# MPU register map
Vendor: Texas Instruments
Peripheral module from a debugger description file (folder awr2544).
Registers are 32-bit, read-only, no defined reset value unless marked. A register's access mark holds for its fields unless they carry their own. Offsets are as the file gives them; lines under a group give offsets from that group; [hi:lo] are bit positions; {n}, {i} and the like mark numbered series; 'fields as' and 'values as' point back to an identical list; <NAME> marks a mode.

## MPU
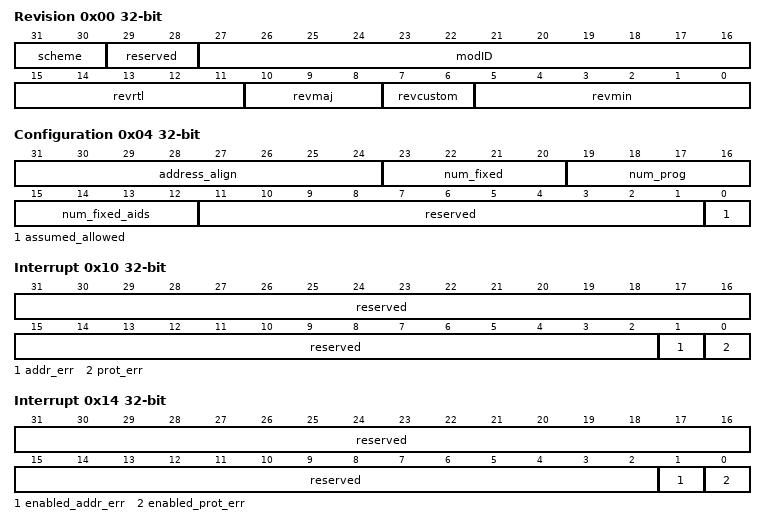
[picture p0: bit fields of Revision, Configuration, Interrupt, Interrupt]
0x00 Revision
  [31:30] scheme
  [29:28] reserved — Always read a s0. Writes have no affect.
  [27:16] modID — Module ID field.
  [15:11] revrtl — RTL revision.Will vary depending on release.
  [10:8] revmaj — Majo revision.
  [7:6] revcustom — Custom revision.
  [5:0] revmin — Minor revision.
0x04 Configuration
  [31:24] address_align — Address alignment for range checking.
  [23:20] num_fixed — Number of fixed address ranges Configurable as 0 or 1.
  [19:16] num_prog — Number of programmable address ranges.Value is determined by configuration
  [15:12] num_fixed_aids — Number of supported AIDs. 0 = no specific AIDs supported (all treated equally) N = PrivIDs from 0 to N-1 supported, others use AIDX
  [11:1] reserved — Always read as 0.
  [0] assumed_allowed — Assumed allowed mode. 0 = assumed disallowed, 1 = assumed allowed
0x10 Interrupt Raw Status/Set access not given
  [31:2] reserved ro — Always read as 0.
  [1] addr_err — Addressing violation error. Raw status is read.Write a 1 to set the status. Writing a 0 has no effect.
  [0] prot_err — Protection violation error. Raw status is read. Write a 1 to set the status. Writing a 0 has no effect.
0x14 Interrupt Enabled Status/Clear access not given
  [31:2] reserved ro — Always read as 0.
  [1] enabled_addr_err — Addressing violation error. Enabled status is read.Write a 1 to clear the status. Writing a 0 has no effect.
  [0] enabled_prot_err — Protection violation error. Enabled status is read. Write a 1 to clear the status. Writing a 0 has no effect.
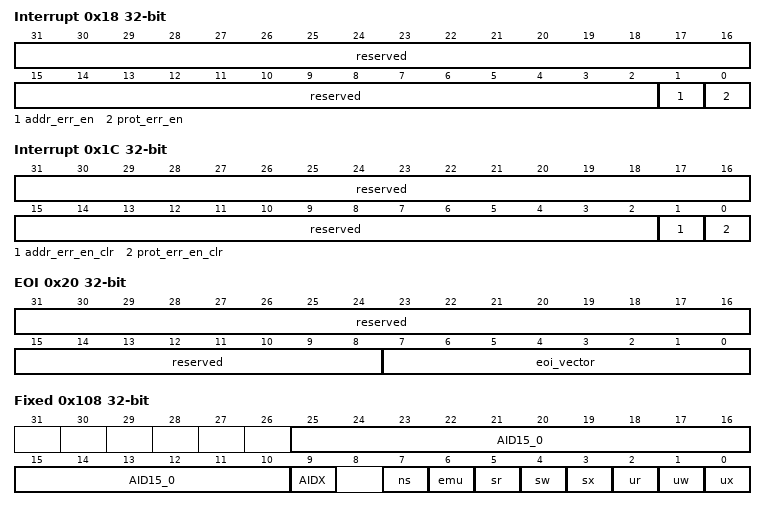
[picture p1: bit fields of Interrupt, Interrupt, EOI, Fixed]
0x18 Interrupt Enable access not given
  [31:2] reserved ro — Always read as 0.
  [1] addr_err_en — Addressing violation error enable. Write a 1 to set the enable. Writing a 0 has no effect.
  [0] prot_err_en — Protection violation error enable. Write a 1 to set the enable. Writing a 0 has no effect.
0x1C Interrupt Enable Clear access not given
  [31:2] reserved ro — Always read as 0.
  [1] addr_err_en_clr — Addressing violation error enable. Write a 1 to clear the enable. Writing a 0 has no effect.
  [0] prot_err_en_clr — Protection violation error enable. Write a 1 to clear the enable. Writing a 0 has no effect.
0x20 EOI access per field
  [31:8] reserved ro — Always read as 0.
  [7:0] eoi_vector rw — EOI vector value.Write this with the interrupt distribution value in the chip. This drives the mpu_eoi_vector output signal.
0x24 Interrupt Vector
  [31:0] intr_vec — Interrupt vector. Reads mpu_intr_vector input signal.
0x100 Fixed Start Address
  [31:0] start_addr — Reserved not used in Design
0x104 Fixed End Address
  [31:0] end_addr — Reserved not used in Design
0x108 Fixed MPPA
  [25:10] AID15_0 — Reserved not used in Design
  [9] AIDX — Reserved not used in Design
  [7] ns — Reserved not used in Design
  [6] emu — Reserved not used in Design
  [5] sr — Reserved not used in Design
  [4] sw — Reserved not used in Design
  [3] sx — Reserved not used in Design
  [2] ur — Reserved not used in Design
  [1] uw — Reserved not used in Design
  [0] ux — Reserved not used in Design
{0x1F0+0x10*i} Programmable {i} Start Address rw (i=1..8)
  [31:0] start_addr — Start address for range N. Defaults to input signal value.
{0x1F4+0x10*i} Programmable {i} End Address rw (i=1..8)
  [31:0] end_addr — End address for range N. Defaults to input signal value.
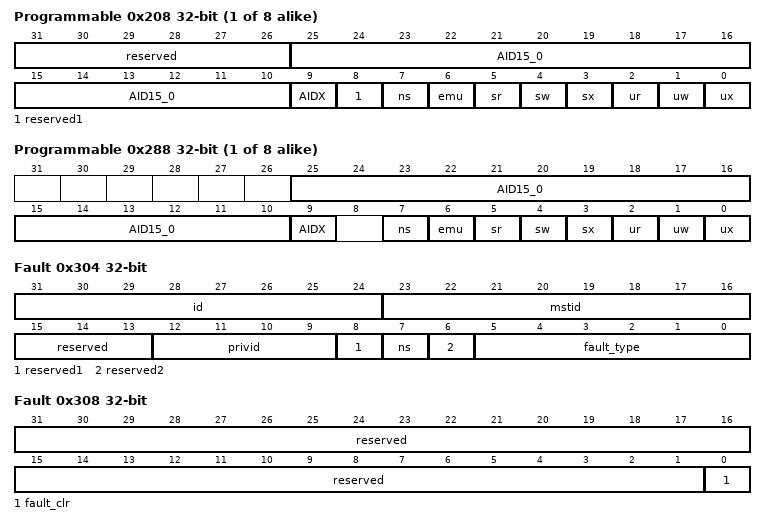
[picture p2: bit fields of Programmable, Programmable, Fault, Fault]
{0x1F8+0x10*i} Programmable {i} MPPA access per field (i=1..8)
  [31:26] reserved ro — Always read as 0.
  [25:10] AID15_0 rw — AIDs checked for this region. Defaults to input value. 0 = AID is not checked for these permissions. 1 = AID is checked for these permissions.
  [9] AIDX rw — Additional AIDs checked. Defaults to input value.
  [8] reserved1 ro — Always read as 0.
  [7] ns rw — Non-secure permission. Defaults to input value.
  [6] emu rw — Debug permission. Defaults to input value.
  [5] sr rw — Supervisor read permission. Defaults to input value.
  [4] sw rw — Supervisor write permission. Defaults to input value.
  [3] sx rw — Supervisor executable permission. Defaults to input value.
  [2] ur rw — User read permission. Defaults to input value.
  [1] uw rw — User write permission. Defaults to input value.
  [0] ux rw — User executable permission. Defaults to input value.
{0x1F0+0x10*i} Programmable {i} Start Address (i=9..16)
  [31:0] start_addr — Reserved not used in Design
{0x1F4+0x10*i} Programmable {i} End Address (i=9..16)
  [31:0] end_addr — Reserved not used in Design
{0x1F8+0x10*i} Programmable {i} MPPA (i=9..16)
  [25:10] AID15_0 — Reserved not used in Design
  [9] AIDX — Reserved not used in Design
  [7] ns — Reserved not used in Design
  [6] emu — Reserved not used in Design
  [5] sr — Reserved not used in Design
  [4] sw — Reserved not used in Design
  [3] sx — Reserved not used in Design
  [2] ur — Reserved not used in Design
  [1] uw — Reserved not used in Design
  [0] ux — Reserved not used in Design
0x300 Fault Address
  [31:0] fault_addr — Fault address.
0x304 Fault Status
  [31:24] id — Transfer ID
  [23:16] mstid — Master ID.
  [15:13] reserved — Always read as 0.
  [12:9] privid — Privilege ID.
  [8] reserved1 — Always read as 0.
  [7] ns — Non-secure access.
  [6] reserved2 — Always read as 0.
  [5:0] fault_type — Fault type. 100000 = supervisor read fault 010000 = supervisor write fault 001000 = supervisor execute fault 000100 = user read fault 000010 = user write fault 000001 = user execute fault 111111 = relaxed cache linefill fault 010010 = relaxed cache writeback fault 000000 = no fault
0x308 Fault Clear access per field
  [31:1] reserved ro — Always read as 0.
  [0] fault_clr wo — Fault clear. Writing a 1 clears the current fault. Writing a 0 has no effect.
